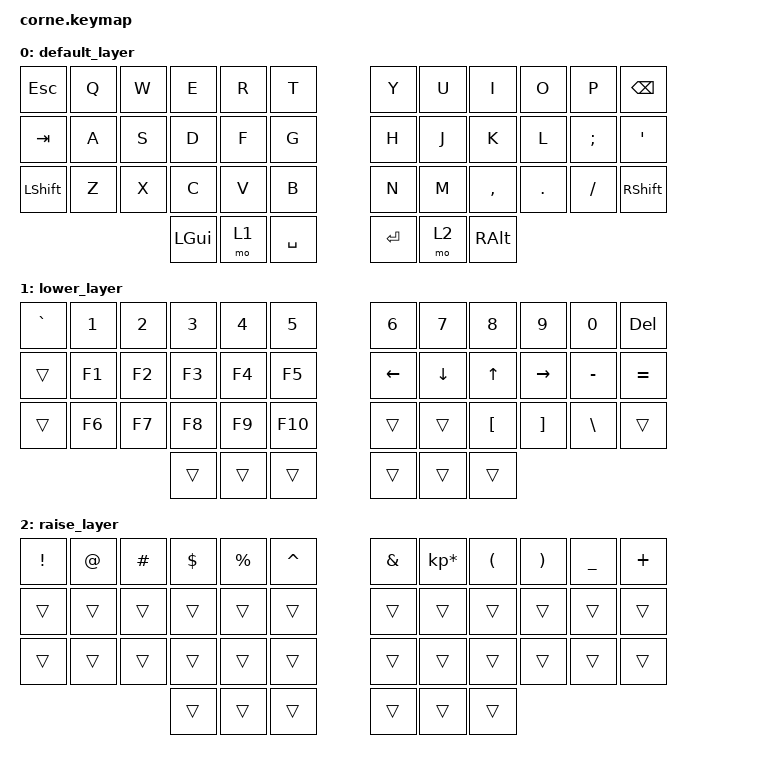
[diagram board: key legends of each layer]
#include <behaviors.dtsi>
#include <dt-bindings/zmk/keys.h>
#include <dt-bindings/zmk/bt.h>

/ {
	keymap {
		compatible = "zmk,keymap";

		default_layer {
			// -----------------------------------------------------------------------------------------
			// | ESC  |  Q  |  W  |  E  |  R  |  T  |   |  Y  |  U  |  I  |  O  |  P  | BSPC |
			// | TAB  |  A  |  S  |  D  |  F  |  G  |   |  H  |  J  |  K  |  L  |  ;  |  '   |
			// | SHFT |  Z  |  X  |  C  |  V  |  B  |   |  N  |  M  |  ,  |  .  |  /  | SHFT |
			//               | GUI | LWR | SPC |   | ENT | RSE | ALT |
			bindings = 
&kp ESC   &kp Q &kp W &kp E &kp R &kp T      &kp Y &kp U &kp I     &kp O   &kp P    &kp BSPC
&kp TAB   &kp A &kp S &kp D &kp F &kp G      &kp H &kp J &kp K     &kp L   &kp SEMI &kp SQT
&kp LSHFT &kp Z &kp X &kp C &kp V &kp B      &kp N &kp M &kp COMMA &kp DOT &kp FSLH &kp RSHFT
                 &kp LGUI &mo 1 &kp SPACE    &kp RET &mo 2 &kp RALT
			>;
		};

		lower_layer {
			bindings = 
&kp GRAVE &kp N1 &kp N2 &kp N3   &kp N4   &kp N5      &kp N6   &kp N7   &kp N8    &kp N9  &kp N0   &kp DEL
&trans    &kp F1 &kp F2 &kp F3   &kp F4   &kp F5       &kp LEFT &kp DOWN &kp UP    &kp RIGHT &kp MINUS &kp EQUAL
&trans    &kp F6 &kp F7 &kp F8   &kp F9   &kp F10       &trans   &trans   &kp LBKT  &kp RBKT &kp BSLH &trans
                 &trans &trans &trans     &trans &trans &trans
			>;
		};

		raise_layer {
			bindings = 
&kp EXCL &kp AT &kp HASH &kp DLLR &kp PRCNT &kp CARET   &kp AMPS &kp KP_MULTIPLY &kp LPAR &kp RPAR &kp UNDER &kp PLUS
&trans   &trans &trans   &trans   &trans    &trans      &trans   &trans          &trans   &trans   &trans    &trans
&trans   &trans &trans   &trans   &trans    &trans      &trans   &trans          &trans   &trans   &trans    &trans
                &trans &trans &trans        &trans &trans &trans
			>;
		};
	};
};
